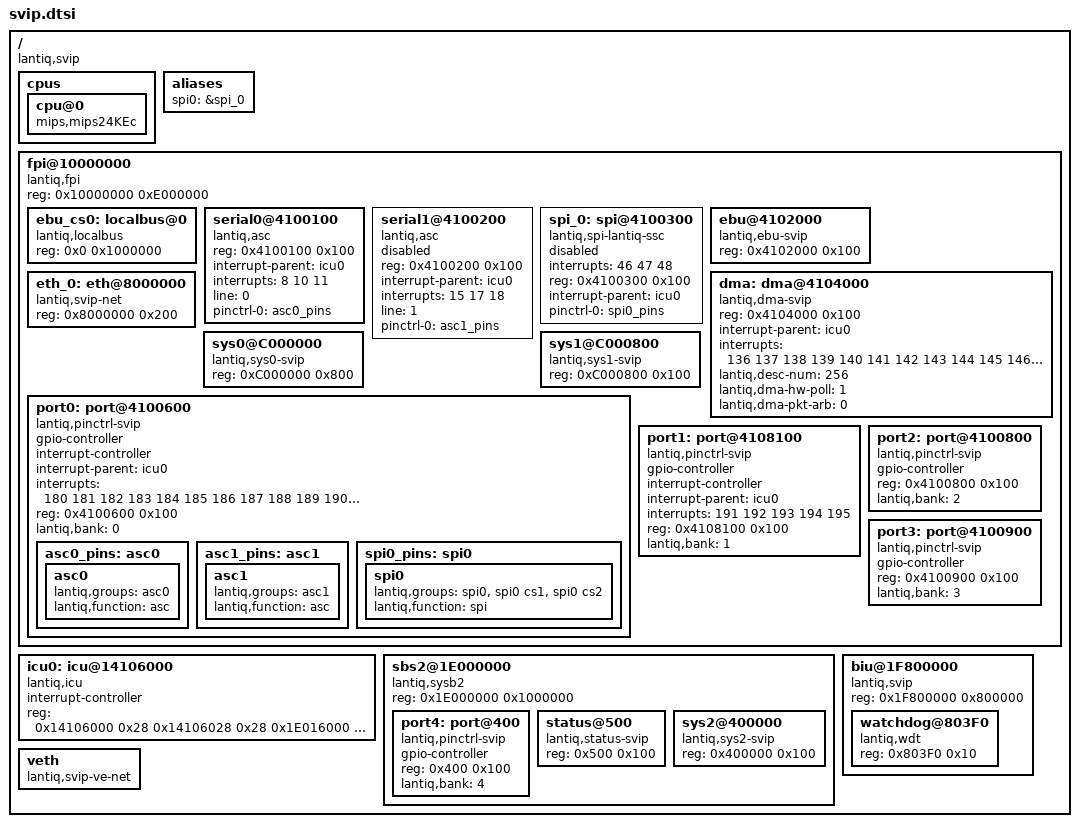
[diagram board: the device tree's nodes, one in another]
/ {
	#address-cells = <1>;
	#size-cells = <1>;
	compatible = "lantiq,svip";

	cpus {
		cpu@0 {
			compatible = "mips,mips24KEc";
		};
	};

	aliases {
		spi0 = &spi_0;
	};

	/* FPI (flexible peripheral interconnect) */
	fpi@10000000 {
		#address-cells = <1>;
		#size-cells = <1>;
		compatible = "lantiq,fpi", "simple-bus";
		reg = <0x10000000 0xE000000>;
		ranges = <0x0 0x10000000 0xE000000>;

		ebu_cs0: localbus@0 {
			#address-cells = <1>;
			#size-cells = <1>;
			compatible = "lantiq,localbus", "simple-bus";
			reg = <0x0 0x1000000>;
			ranges = <0x0 0x0 0x1000000>;
		};
		serial0@4100100 {
			compatible = "lantiq,asc";
			reg = <0x4100100 0x100>;
			interrupt-parent = <&icu0>;
			interrupts = <8 10 11>;
			line = <0>;
			pinctrl-names = "default";
			pinctrl-0 = <&asc0_pins>;
		};
		serial1@4100200 {
			status = "disabled";
			compatible = "lantiq,asc";
			reg = <0x4100200 0x100>;
			interrupt-parent = <&icu0>;
			interrupts = <15 17 18>;
			line = <1>;
			pinctrl-names = "default";
			pinctrl-0 = <&asc1_pins>;
		};
		spi_0: spi@4100300 {
			#address-cells = <1>;
			#size-cells = <0>;
			status = "disabled";
			compatible = "lantiq,spi-lantiq-ssc", "lantiq,spi-xway-csi";
			interrupts = <46 47 48>;
			reg = <0x4100300 0x100>;
			interrupt-parent = <&icu0>;
			pinctrl-names = "default";
			pinctrl-0 = <&spi0_pins>;
		};
		ebu@4102000 {
			compatible = "lantiq,ebu-svip";
			reg = <0x4102000 0x100>;
		};
		dma: dma@4104000 {
			compatible = "lantiq,dma-svip";
			reg = <0x4104000 0x100>;
			interrupt-parent = <&icu0>;
			interrupts = <136 137 138 139 140 141 142 143 144 145 146 147 148 149 150 151 152 153 154 155 156 157 158 159>;
			lantiq,desc-num = <256>;
			lantiq,dma-hw-poll = <1>;
			lantiq,dma-pkt-arb = <0>;
		};
		eth_0: eth@8000000 {
			compatible = "lantiq,svip-net";
			reg = <0x8000000 0x200>;
		};
		sys0@C000000 {
			compatible = "lantiq,sys0-svip";
			reg = <0xC000000 0x800>;
		};
		sys1@C000800 {
			compatible = "lantiq,sys1-svip";
			reg = <0xC000800 0x100>;
		};
		port0: port@4100600 {
			compatible = "lantiq,pinctrl-svip";
			gpio-controller;
			#gpio-cells = <2>;
			interrupt-controller;
			#interrupt-cells = <2>;
			interrupt-parent = <&icu0>;
			interrupts = <180 181 182 183 184 185 186 187 188 189 190 196>;
			reg = <0x4100600 0x100>;
			lantiq,bank = <0>;

			asc0_pins: asc0 {
				asc0 {
					lantiq,groups = "asc0";
					lantiq,function = "asc";
				};
			};
			asc1_pins: asc1 {
				asc1 {
					lantiq,groups = "asc1";
					lantiq,function = "asc";
				};
			};
			spi0_pins: spi0 {
				spi0 {
					lantiq,groups = "spi0", "spi0 cs1", "spi0 cs2";
					lantiq,function = "spi";
				};
			};
		};
		port1: port@4108100 {
			compatible = "lantiq,pinctrl-svip";
			gpio-controller;
			#gpio-cells = <2>;
			interrupt-controller;
			#interrupt-cells = <2>;
			interrupt-parent = <&icu0>;
			interrupts = <191 192 193 194 195>;
			reg = <0x4108100 0x100>;
			lantiq,bank = <1>;
		};
		port2: port@4100800 {
			compatible = "lantiq,pinctrl-svip";
			gpio-controller;
			#gpio-cells = <2>;
			reg = <0x4100800 0x100>;
			lantiq,bank = <2>;
		};
		port3: port@4100900 {
			compatible = "lantiq,pinctrl-svip";
			gpio-controller;
			#gpio-cells = <2>;
			reg = <0x4100900 0x100>;
			lantiq,bank = <3>;
		};
	};

	/* ICU0 resides on two busses: fpi and sbs2. Driver implementation (irq.c) requires exactly 6 memory regions to be specified, therefore icu0 can't be separated into two parts and placed in both fpi and sbs2 nodes. Driver implementation should be reviewed. */
	icu0: icu@14106000 {
		#interrupt-cells = <1>;
		interrupt-controller;
		compatible = "lantiq,icu";
		reg =  <0x14106000 0x28
			0x14106028 0x28
			0x1E016000 0x28
			0x1E016028 0x28
			0x14106050 0x28
			0x14106078 0x28>;
	};

	/* SBS2 (SRAM bus system 2) */
	sbs2@1E000000 {
		#address-cells = <1>;
		#size-cells = <1>;
		compatible = "lantiq,sysb2", "simple-bus";
		reg = <0x1E000000 0x1000000>;
		ranges = <0x0 0x1E000000 0x1000000>;

		port4: port@400 {
			compatible = "lantiq,pinctrl-svip";
			gpio-controller;
			#gpio-cells = <2>;
			reg = <0x400 0x100>;
			lantiq,bank = <4>;
		};
		status@500 {
			compatible = "lantiq,status-svip";
			reg = <0x500 0x100>;
		};
		sys2@400000 {
			compatible = "lantiq,sys2-svip";
			reg = <0x400000 0x100>;
		};
	};

	biu@1F800000 {
		#address-cells = <1>;
		#size-cells = <1>;
		compatible = "lantiq,svip";
		reg = <0x1F800000 0x800000>;
		ranges = <0x0 0x1F800000 0x800000>;

		watchdog@803F0 {
			compatible = "lantiq,wdt";
			reg = <0x803F0 0x10>;
		};
	};

	veth {
		compatible = "lantiq,svip-ve-net";
	};
};
